AUTOSAR XML (schema 4-0-3)
package /ComponentTypes
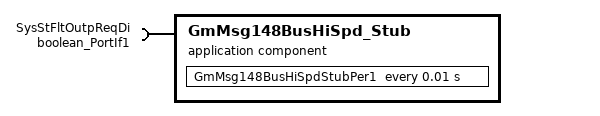
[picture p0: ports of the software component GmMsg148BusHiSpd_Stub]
  application sw component type GmMsg148BusHiSpd_Stub
    require port SysStFltOutpReqDi: nonqueued-receiver-com-spec{data-element=Logl, filter=data-filter-type=ALWAYS, init-value=0}, required-interface=boolean_PortIf1
    behavior GmMsg148BusHiSpd_Stub_InternalBehavior
      timing event TMT_GmMsg148BusHiSpdPer1: start-on-event=GmMsg148BusHiSpdStubPer1, period=0.01
      runnable GmMsg148BusHiSpdStubPer1
        data-receive-point-by-arguments:
          access REC_SysStFltOutpReqDi_Logl: accessed-variable=SysStFltOutpReqDi.Logl
  swc implementation GmMsg148BusHiSpd_Stub_Implementation: behavior=GmMsg148BusHiSpd_Stub_InternalBehavior
    code-descriptors:
      code Default: artifact-descriptors=autosar-engineering-object={short-label=Default, category=SWSRC}
